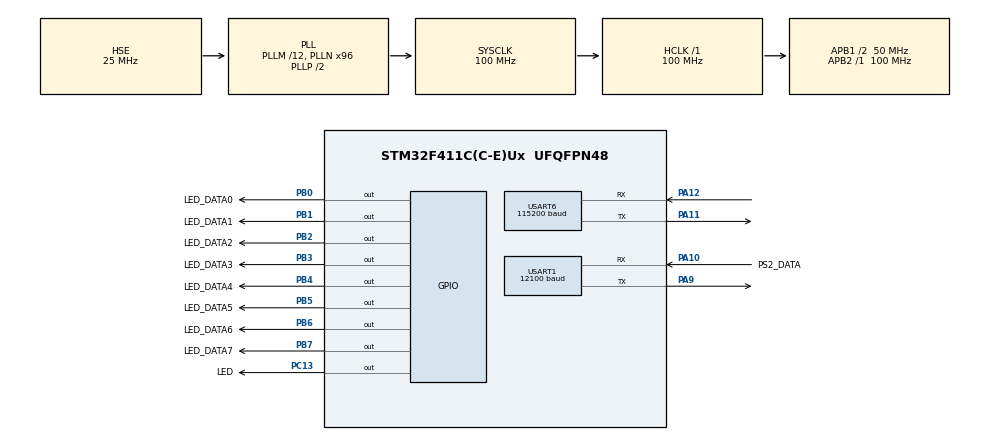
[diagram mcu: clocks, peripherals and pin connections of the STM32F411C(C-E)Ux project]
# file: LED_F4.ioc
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Dma.Request0=TIM1_UP
Dma.Request1=USART1_RX
Dma.TIM1_UP.0.Direction=DMA_MEMORY_TO_PERIPH
Dma.TIM1_UP.0.FIFOMode=DMA_FIFOMODE_ENABLE
Dma.TIM1_UP.0.FIFOThreshold=DMA_FIFO_THRESHOLD_FULL
Dma.TIM1_UP.0.Instance=DMA2_Stream5
Dma.TIM1_UP.0.MemBurst=DMA_MBURST_INC16
Dma.TIM1_UP.0.MemDataAlignment=DMA_MDATAALIGN_BYTE
Dma.TIM1_UP.0.MemInc=DMA_MINC_ENABLE
Dma.TIM1_UP.0.Mode=DMA_NORMAL
Dma.TIM1_UP.0.PeriphBurst=DMA_PBURST_SINGLE
Dma.TIM1_UP.0.PeriphDataAlignment=DMA_PDATAALIGN_BYTE
Dma.TIM1_UP.0.PeriphInc=DMA_PINC_DISABLE
Dma.TIM1_UP.0.Priority=DMA_PRIORITY_MEDIUM
Dma.USART1_RX.1.Direction=DMA_PERIPH_TO_MEMORY
Dma.USART1_RX.1.FIFOMode=DMA_FIFOMODE_DISABLE
Dma.USART1_RX.1.Instance=DMA2_Stream2
Dma.USART1_RX.1.MemDataAlignment=DMA_MDATAALIGN_BYTE
Dma.USART1_RX.1.MemInc=DMA_MINC_ENABLE
Dma.USART1_RX.1.Mode=DMA_CIRCULAR
Dma.USART1_RX.1.PeriphDataAlignment=DMA_PDATAALIGN_BYTE
Dma.USART1_RX.1.PeriphInc=DMA_PINC_DISABLE
Dma.USART1_RX.1.Priority=DMA_PRIORITY_MEDIUM
Mcu.Family=STM32F4
Mcu.Name=STM32F411C(C-E)Ux
Mcu.Package=UFQFPN48
NVIC.DMA2_Stream2_IRQn=true\:0\:0\:false\:false\:true\:false\:true
NVIC.DMA2_Stream5_IRQn=true\:0\:0\:false\:false\:true\:false\:true
NVIC.PriorityGroup=NVIC_PRIORITYGROUP_4
NVIC.USART1_IRQn=true\:0\:0\:false\:false\:true\:true\:true
NVIC.USART6_IRQn=true\:0\:0\:false\:false\:true\:true\:true
PA10.GPIO_Label=PS2_DATA
PA10.GPIO_PuPd=GPIO_PULLUP
PA10.Mode=Asynchronous
PA10.Signal=USART1_RX
PA11.Mode=Asynchronous
PA11.Signal=USART6_TX
PA12.Mode=Asynchronous
PA12.Signal=USART6_RX
PA13.Mode=Serial_Wire
PA13.Signal=SYS_JTMS-SWDIO
PA14.Mode=Serial_Wire
PA14.Signal=SYS_JTCK-SWCLK
PA9.Mode=Asynchronous
PA9.Signal=USART1_TX
PB0.GPIO_Label=LED_DATA0
PB0.GPIO_Speed=GPIO_SPEED_FREQ_VERY_HIGH
PB0.Signal=GPIO_Output
PB1.GPIO_Label=LED_DATA1
PB1.GPIO_Speed=GPIO_SPEED_FREQ_VERY_HIGH
PB1.PinState=GPIO_PIN_RESET
PB1.Signal=GPIO_Output
PB2.GPIO_Label=LED_DATA2
PB2.GPIO_Speed=GPIO_SPEED_FREQ_VERY_HIGH
PB2.PinState=GPIO_PIN_RESET
PB2.Signal=GPIO_Output
PB3.GPIO_Label=LED_DATA3
PB3.GPIO_ModeDefaultOutputPP=GPIO_MODE_OUTPUT_PP
PB3.GPIO_Speed=GPIO_SPEED_FREQ_VERY_HIGH
PB3.PinState=GPIO_PIN_RESET
PB3.Signal=GPIO_Output
PB4.GPIO_Label=LED_DATA4
PB4.GPIO_Speed=GPIO_SPEED_FREQ_VERY_HIGH
PB4.PinState=GPIO_PIN_RESET
PB4.Signal=GPIO_Output
PB5.GPIO_Label=LED_DATA5
PB5.GPIO_Speed=GPIO_SPEED_FREQ_VERY_HIGH
PB5.Signal=GPIO_Output
PB6.GPIO_Label=LED_DATA6
PB6.GPIO_Speed=GPIO_SPEED_FREQ_VERY_HIGH
PB6.Signal=GPIO_Output
PB7.GPIO_Label=LED_DATA7
PB7.GPIO_Speed=GPIO_SPEED_FREQ_VERY_HIGH
PB7.Signal=GPIO_Output
PC13-ANTI_TAMP.GPIO_Label=LED
PC13-ANTI_TAMP.GPIO_ModeDefaultOutputPP=GPIO_MODE_OUTPUT_PP
PC13-ANTI_TAMP.GPIO_PuPd=GPIO_NOPULL
PC13-ANTI_TAMP.PinState=GPIO_PIN_SET
PC13-ANTI_TAMP.Signal=GPIO_Output
PH0\ -\ OSC_IN.Mode=HSE-External-Oscillator
PH0\ -\ OSC_IN.Signal=RCC_OSC_IN
PH1\ -\ OSC_OUT.Mode=HSE-External-Oscillator
PH1\ -\ OSC_OUT.Signal=RCC_OSC_OUT
ProjectManager.HeapSize=0x200
ProjectManager.StackSize=0x400
ProjectManager.TargetToolchain=Makefile
RCC.48MHZClocksFreq_Value=50000000
RCC.AHBFreq_Value=100000000
RCC.APB1CLKDivider=RCC_HCLK_DIV2
RCC.APB1Freq_Value=50000000
RCC.APB1TimFreq_Value=100000000
RCC.APB2Freq_Value=100000000
RCC.APB2TimFreq_Value=100000000
RCC.CortexFreq_Value=100000000
RCC.HCLKFreq_Value=100000000
RCC.HSE_VALUE=25000000
RCC.HSI_VALUE=16000000
RCC.LSE_VALUE=32768
RCC.PLLM=12
RCC.PLLN=96
RCC.PLLSourceVirtual=RCC_PLLSOURCE_HSE
RCC.RCC_RTC_Clock_Source=RCC_RTCCLKSOURCE_LSI
RCC.RCC_RTC_Clock_SourceVirtual=RCC_RTCCLKSOURCE_LSI
RCC.SYSCLKFreq_VALUE=100000000
RCC.SYSCLKSource=RCC_SYSCLKSOURCE_PLLCLK
RCC.VCOOutputFreq_Value=200000000
TIM1.Period=29
TIM1.Prescaler=0
USART1.BaudRate=12100
USART1.Mode=MODE_RX
USART1.OverSampling=UART_OVERSAMPLING_8
USART1.Parity=PARITY_ODD
USART1.VirtualMode=VM_ASYNC
USART1.WordLength=WORDLENGTH_9B
USART6.BaudRate=115200
USART6.Mode=MODE_TX
USART6.OverSampling=UART_OVERSAMPLING_8
USART6.Parity=PARITY_EVEN
USART6.VirtualMode=VM_ASYNC
USART6.WordLength=WORDLENGTH_9B
VP_TIM1_VS_ClockSourceINT.Mode=Internal
board=custom

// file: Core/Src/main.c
/* USER CODE BEGIN Header */
/**
  ******************************************************************************
  * @file           : main.c
  * @brief          : Main program body
  ******************************************************************************
  * @attention
  *
  * <h2><center>&copy; Copyright (c) 2021 STMicroelectronics.
  * All rights reserved.</center></h2>
  *
  * This software component is licensed by ST under BSD 3-Clause license,
  * the "License"; You may not use this file except in compliance with the
  * License. You may obtain a copy of the License at:
  *                        opensource.org/licenses/BSD-3-Clause
  *
  ******************************************************************************
  */
/* USER CODE END Header */
#include "main.h"
#include "dma.h"
#include "tim.h"
#include "usart.h"
#include "gpio.h"

/* USER CODE BEGIN Includes */
#include "led.h"

/* USER CODE END Includes */

/* USER CODE BEGIN PV */

// extern uint8_t led_data[72 * LED_num];
// extern TIM_HandleTypeDef htim1;
// extern DMA_HandleTypeDef hdma_tim1_up;
// extern TIM_HandleTypeDef htim2;
// extern TIM_HandleTypeDef htim3;
// extern DMA_HandleTypeDef hdma_tim2_ch3_up;
// extern DMA_HandleTypeDef hdma_memtomem_dma2_stream0;

/* USER CODE END PV */

void SystemClock_Config(void);

int main(void)
{

  /* MCU Configuration--------------------------------------------------------*/

  /* Reset of all peripherals, Initializes the Flash interface and the Systick. */
  HAL_Init();

  /* Configure the system clock */
  SystemClock_Config();

  /* Initialize all configured peripherals */
  MX_DMA_Init();
  MX_TIM1_Init();
  MX_GPIO_Init();
  MX_USART6_UART_Init();
  MX_USART1_UART_Init();
  /* USER CODE BEGIN 2 */

  LED_Data_Init();
  // LED_Data_Convert();
  // HAL_PS2_Receive_Start_DMA(&htim1, TIM_CHANNEL_1, (uint8_t *)Rx_data, 11);
  HAL_UART_Receive_DMA(&huart1, (uint8_t *)&uart_rx_data, 1);
  // HAL_LED_Transmit_Start_DMA(&htim1, (uint8_t *)LED_Data_Transmit, sizeof(LED_Data_Transmit));

  // GPIOB->BSRR = 0;

  /* USER CODE END 2 */

  /* Infinite loop */
  while (1)
  {

    /* USER CODE BEGIN 3 */

    HAL_GPIO_TogglePin(LED_GPIO_Port, LED_Pin);
    // HAL_UART_Transmit_IT(&huart6, (uint8_t *)&"test", 5);
    // PS2_Data_Handle();
    // HAL_UART_Transmit(&huart2, (uint8_t *)"abcde", 6, 10);
    // HAL_Delay(50);

    _main();
  }
  /* USER CODE END 3 */
}

void SystemClock_Config(void)
{
  RCC_OscInitTypeDef RCC_OscInitStruct = {0};
  RCC_ClkInitTypeDef RCC_ClkInitStruct = {0};

  /** Configure the main internal regulator output voltage
  */
  __HAL_RCC_PWR_CLK_ENABLE();
  __HAL_PWR_VOLTAGESCALING_CONFIG(PWR_REGULATOR_VOLTAGE_SCALE1);
  /** Initializes the RCC Oscillators according to the specified parameters
  * in the RCC_OscInitTypeDef structure.
  */
  RCC_OscInitStruct.OscillatorType = RCC_OSCILLATORTYPE_HSE;
  RCC_OscInitStruct.HSEState = RCC_HSE_ON;
  RCC_OscInitStruct.PLL.PLLState = RCC_PLL_ON;
  RCC_OscInitStruct.PLL.PLLSource = RCC_PLLSOURCE_HSE;
  RCC_OscInitStruct.PLL.PLLM = 12;
  RCC_OscInitStruct.PLL.PLLN = 96;
  RCC_OscInitStruct.PLL.PLLP = RCC_PLLP_DIV2;
  RCC_OscInitStruct.PLL.PLLQ = 4;
  if (HAL_RCC_OscConfig(&RCC_OscInitStruct) != HAL_OK)
  {
    Error_Handler();
  }
  /** Initializes the CPU, AHB and APB buses clocks
  */
  RCC_ClkInitStruct.ClockType = RCC_CLOCKTYPE_HCLK|RCC_CLOCKTYPE_SYSCLK
                              |RCC_CLOCKTYPE_PCLK1|RCC_CLOCKTYPE_PCLK2;
  RCC_ClkInitStruct.SYSCLKSource = RCC_SYSCLKSOURCE_PLLCLK;
  RCC_ClkInitStruct.AHBCLKDivider = RCC_SYSCLK_DIV1;
  RCC_ClkInitStruct.APB1CLKDivider = RCC_HCLK_DIV2;
  RCC_ClkInitStruct.APB2CLKDivider = RCC_HCLK_DIV1;

  if (HAL_RCC_ClockConfig(&RCC_ClkInitStruct, FLASH_LATENCY_3) != HAL_OK)
  {
    Error_Handler();
  }
}

void Error_Handler(void)
{
  __disable_irq();
  while (1)
  {
  }
}

/************************ (C) COPYRIGHT STMicroelectronics *****END OF FILE****/
